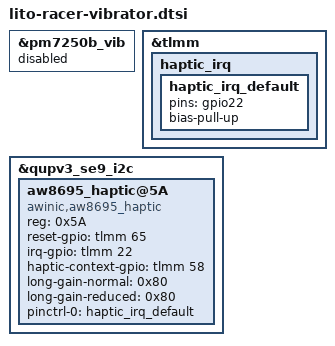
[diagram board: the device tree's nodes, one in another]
&pm7250b_vib{
	status = "disabled";
};

&tlmm{
	haptic_irq {
		haptic_irq_default: haptic_irq_default {
			pins = "gpio22";
			bias-pull-up;
		};
	};
};

&qupv3_se9_i2c {
	status = "okay";

	aw8695_haptic@5A {
		compatible = "awinic,aw8695_haptic";
		reg = <0x5A>;
		reset-gpio = <&tlmm 65 0>;
		irq-gpio = <&tlmm 22 0>;
		haptic-context-gpio = <&tlmm 58 0>;
		long-gain-normal = <0x80>;
		long-gain-reduced = <0x80>;
		pinctrl-names = "default";
		pinctrl-0 = <&haptic_irq_default>;
		status = "okay";
	};
};
